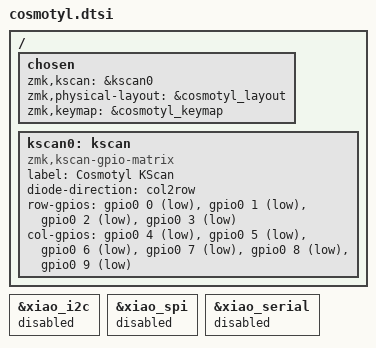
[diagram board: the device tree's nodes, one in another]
/*
 * Copyright (c) 2022 The ZMK Contributors
 *
 * SPDX-License-Identifier: MIT
 */
/* Cosmotyl Keyboard Device Tree Source */

#include "cosmotyl-layout.dtsi"

/ {
    chosen {
        zmk,kscan = &kscan0;
        zmk,physical-layout = &cosmotyl_layout;
        zmk,keymap = &cosmotyl_keymap;
    };

    kscan0: kscan {
        compatible = "zmk,kscan-gpio-matrix";
        label = "Cosmotyl KScan";
        diode-direction = "col2row";
        row-gpios = <&gpio0 0 GPIO_ACTIVE_LOW>,  // Reihe 0
                    <&gpio0 1 GPIO_ACTIVE_LOW>,  // Reihe 1
                    <&gpio0 2 GPIO_ACTIVE_LOW>,  // Reihe 2
                    <&gpio0 3 GPIO_ACTIVE_LOW>;  // Reihe 3
        col-gpios = <&gpio0 4 GPIO_ACTIVE_LOW>,  // Spalte 0
                    <&gpio0 5 GPIO_ACTIVE_LOW>,  // Spalte 1
                    <&gpio0 6 GPIO_ACTIVE_LOW>,  // Spalte 2
                    <&gpio0 7 GPIO_ACTIVE_LOW>,  // Spalte 3
                    <&gpio0 8 GPIO_ACTIVE_LOW>,  // Spalte 4
                    <&gpio0 9 GPIO_ACTIVE_LOW>;  // Spalte 5
    };
};

&xiao_i2c { status = "disabled"; };
&xiao_spi { status = "disabled"; };
&xiao_serial { status = "disabled"; };
